# R7FA8M1AH register map
Vendor: Renesas; Series: RA8; File version: 1.2
CPU: CM85 r0p0, little endian, MPU, FPU, VTOR, 4 interrupt priority bits
Registers are 32-bit, read-write, reset 0x0 unless marked. A register's access mark holds for its fields unless they carry their own. Offsets are from the block's base; [hi:lo] are bit positions; 'fields as' and 'values as' point back to an identical list.

## SCI0 (part 1 of 2) — Serial Communication Interface 0
Base 0x40358000
Same registers: SCI1 0x40358100, SCI2 0x40358200, SCI3 0x40358300, SCI4 0x40358400, SCI9 0x40358900, SCI0_NS 0x50358000, SCI1_NS 0x50358100, SCI2_NS 0x50358200, SCI3_NS 0x50358300, SCI4_NS 0x50358400, SCI9_NS 0x50358900
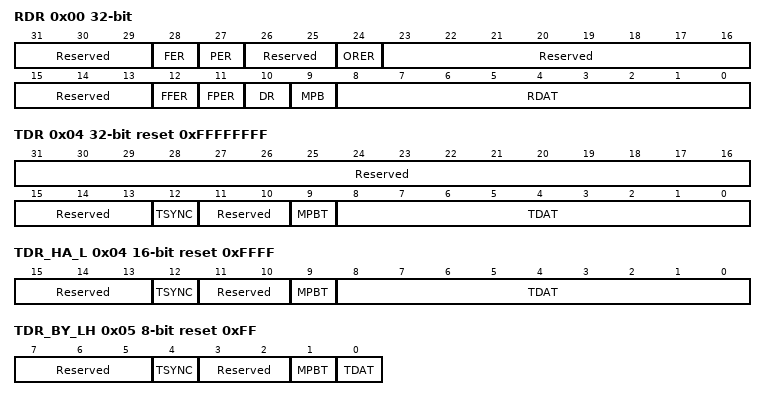
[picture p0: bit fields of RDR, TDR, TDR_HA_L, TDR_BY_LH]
0x00 RDR ro — Received Data Register
  [31:29] Reserved — These bits are read as 000.
  [28] FER — Framing Error Flag
    0=No framing error occurred; 1=A framing error has occurred
  [27] PER — Parity Error Flag
    0=No parity error occurred; 1=A parity error has occurred
  [26:25] Reserved — These bits are read as 00.
  [24] ORER — Overrun error flag
    0=No overrun error occurred; 1=An overrun error has occurred
  [23:13] Reserved — These bits are read as 00000000000.
  [12] FFER — Framing error flag
    0=No framing error occurred at the first data of received-FIFO (RDR); 1=A framing error has occurred at the first data of received-FIFO (RDR)
  [11] FPER — Parity error flag
    0=No parity error occurred at the first data of received-FIFO (RDR); 1=A parity error has occurred at the first data of received-FIFO (RDR)
  [10] DR — Receive data ready flag
    0=Receiving is in progress, or no received data has remained in received-FIFO (RDR) after normally completed receiving; 1=Next receive data has not been received for a period after normal completed receiving
  [9] MPB — Multiprocessor bit flag
    0=Data transmission cycles; 1=ID transmission cycles
  [8:0] RDAT — Received data.
0x04 TDR reset 0xFFFFFFFF — Transmission Data Register
  [31:16] Reserved — These bits are read as 1111111111111111. The write value should be 1111111111111111.
  [15:13] Reserved — These bits are read as 111. The write value should be 111.
  [12] TSYNC — Transmit sync data bit.
    0=Start bit outputs data Sync; 1=Start bit outputs command Sync
  [11:10] Reserved — These bits are read as 11. The write value should be 11.
  [9] MPBT — Multi-processor transfer bit flag
    0=Data transmission cycles; 1=ID transmission cycles
  [8:0] TDAT — Transmission data.
0x04 TDR_HA_L 16-bit reset 0xFFFF — Transmission Data Register
  [15:13] Reserved — These bits are read as 111. The write value should be 111.
  [12] TSYNC — Transmit sync data bit.
    values as TDR.TSYNC
  [11:10] Reserved — These bits are read as 11. The write value should be 11.
  [9] MPBT — Multi-processor transfer bit flag
    0=Data transmission cycles; 1=ID transmission cycles
  [8:0] TDAT — Transmission data.
0x04 TDR_BY_LL 8-bit reset 0xFF — Transmission Data Register
  [7:0] TDAT — Transmission data.
0x05 TDR_BY_LH 8-bit reset 0xFF — Transmission Data Register
  [7:5] Reserved — These bits are read as 111. The write value should be 111.
  [4] TSYNC — Transmit sync data bit.
    values as TDR.TSYNC
  [3:2] Reserved — These bits are read as 11. The write value should be 11.
  [1] MPBT — Multi-processor transfer bit flag
    0=Data transmission cycles; 1=ID transmission cycles
  [0] TDAT — Transmission data.
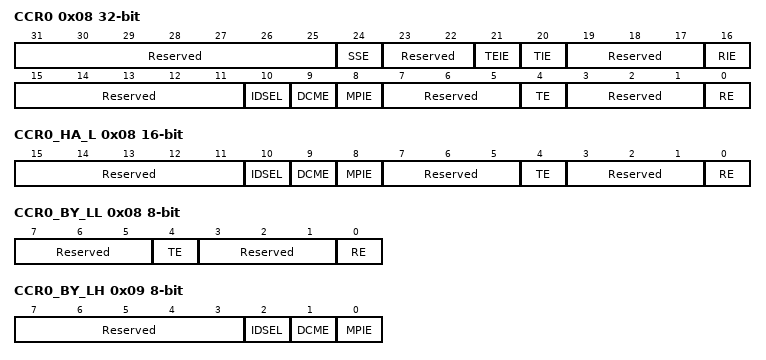
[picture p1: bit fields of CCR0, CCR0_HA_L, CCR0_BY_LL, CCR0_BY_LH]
0x08 CCR0 — Common Control Register 0
  [31:25] Reserved — These bits are read as 0000000. The write value should be 0000000.
  [24] SSE — SSn# Pin Function Enable
    0=SSn# pin function is disabled; 1=SSn# pin function is enabled
  [23:22] Reserved — These bits are read as 00. The write value should be 00.
  [21] TEIE — Transmit End Interrupt Enable
    0=A TEI interrupt request is disabled; 1=A TEI interrupt request is enabled
  [20] TIE — Transmit Interrupt Enable
    0=A TXI interrupt request is disabled; 1=A TXI interrupt request is enabled
  [19:17] Reserved — These bits are read as 000. The write value should be 000.
  [16] RIE — Receive Interrupt Enable
    0=RXI and ERI interrupt requests are disabled; 1=RXI and ERI interrupt requests are enabled
  [15:11] Reserved — These bits are read as 00000. The write value should be 00000.
  [10] IDSEL — ID frame select Bit
    0=It's always compared data in spite of the value of the MPB bit; 1=It's compared data when the MPB bit is “1” ( ID frame ) only
  [9] DCME read-modifies — Data Compare Match Enable
    0=Address match function is disabled; 1=Address match function is enabled
  [8] MPIE read-modifies — Multi-Processor Interrupt Enable
    0=Normal reception; 1=When the data with the multi-processor bit set to "0" is received, the data is not read, and setting the status flags RDRF,ORER FER ,MER ,SYER , PFER and SBER to "1" is disabled. When the data with the multiprocessor bit set to "1" is received, the MPIE bit is automatically cleared to "0", and normal reception is resumed.
  [7:5] Reserved — These bits are read as 000. The write value should be 000.
  [4] TE — Transmit Enable
    0=Serial transmission is disabled; 1=Serial transmission is enabled
  [3:1] Reserved — These bits are read as 000. The write value should be 000.
  [0] RE — Receive Enable
    0=Serial reception is disabled; 1=Serial reception is enabled
0x08 CCR0_HA_L 16-bit — Common Control Register 0
  [15:11] Reserved — These bits are read as 00000. The write value should be 00000.
  [10] IDSEL — ID frame select Bit
    values as CCR0.IDSEL
  [9] DCME read-modifies — Data Compare Match Enable
    values as CCR0.DCME
  [8] MPIE read-modifies — Multi-Processor Interrupt Enable
    values as CCR0.MPIE
  [7:5] Reserved — These bits are read as 000. The write value should be 000.
  [4] TE — Transmit Enable
    values as CCR0.TE
  [3:1] Reserved — These bits are read as 000. The write value should be 000.
  [0] RE — Receive Enable
    values as CCR0.RE
0x08 CCR0_BY_LL 8-bit — Common Control Register 0
  [7:5] Reserved — These bits are read as 000. The write value should be 000.
  [4] TE — Transmit Enable
    values as CCR0.TE
  [3:1] Reserved — These bits are read as 000. The write value should be 000.
  [0] RE — Receive Enable
    values as CCR0.RE
0x09 CCR0_BY_LH 8-bit — Common Control Register 0
  [7:3] Reserved — These bits are read as 00000. The write value should be 00000.
  [2] IDSEL — ID frame select Bit
    values as CCR0.IDSEL
  [1] DCME read-modifies — Data Compare Match Enable
    values as CCR0.DCME
  [0] MPIE read-modifies — Multi-Processor Interrupt Enable
    values as CCR0.MPIE
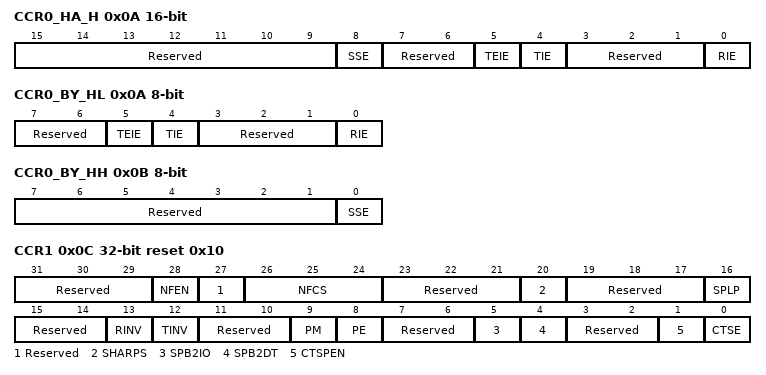
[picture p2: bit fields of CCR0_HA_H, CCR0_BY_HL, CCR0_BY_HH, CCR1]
0x0A CCR0_HA_H 16-bit — Common Control Register 0
  [15:9] Reserved — These bits are read as 0000000. The write value should be 0000000.
  [8] SSE — SSn# Pin Function Enable
    values as CCR0.SSE
  [7:6] Reserved — These bits are read as 00. The write value should be 00.
  [5] TEIE — Transmit End Interrupt Enable
    values as CCR0.TEIE
  [4] TIE — Transmit Interrupt Enable
    values as CCR0.TIE
  [3:1] Reserved — These bits are read as 000. The write value should be 000.
  [0] RIE — Receive Interrupt Enable
    values as CCR0.RIE
0x0A CCR0_BY_HL 8-bit — Common Control Register 0
  [7:6] Reserved — These bits are read as 00. The write value should be 00.
  [5] TEIE — Transmit End Interrupt Enable
    values as CCR0.TEIE
  [4] TIE — Transmit Interrupt Enable
    values as CCR0.TIE
  [3:1] Reserved — These bits are read as 000. The write value should be 000.
  [0] RIE — Receive Interrupt Enable
    values as CCR0.RIE
0x0B CCR0_BY_HH 8-bit — Common Control Register 0
  [7:1] Reserved — These bits are read as 0000000. The write value should be 0000000.
  [0] SSE — SSn# Pin Function Enable
    values as CCR0.SSE
0x0C CCR1 reset 0x10 — Common Control Register 1
  [31:29] Reserved — These bits are read as 000. The write value should be 000.
  [28] NFEN — Digital Noise Filter Function Enable
    0=Noise cancellation function for the RXDn/TXDn input signal is disabled; 1=Noise cancellation function for the RXDn/TXDn input signal is enabled
  [27] Reserved — This bit is read as 0. The write value should be 0.
  [26:24] NFCS — Noise Filter Clock Select
    0=The base clock divided by 1 is used with the noise filter; 1=The on-chip baud rate generator clock divided by 1 is used; 0b=with the noise filter; 2=The on-chip baud rate generator clock divided by 2 is used; 0b=with the noise filter; 3=The on-chip baud rate generator clock divided by 4 is used; 0b=with the noise filter; 4=The on-chip baud rate generator clock divided by 8 is used; 0b=with the noise filter; other=others (Settings other than above are prohibited.)
  [23:21] Reserved — These bits are read as 000. The write value should be 000.
  [20] SHARPS — TxD/RxD Pin Multiplexing Select
    0=The TxD and RxD pins are independent; 1=The TxD and RxD signals are multiplexed on the same pin
  [19:17] Reserved — These bits are read as 000. The write value should be 000.
  [16] SPLP — Serial communication Port LoopBack
    0=Normal mode; 1=Loopback mode
  [15:14] Reserved — These bits are read as 00. The write value should be 00.
  [13] RINV — RxD invert bit
    0=Received data from RxD is input directly; 1=Received data from RxD is inverted and input
  [12] TINV — TxD invert bit
    0=Transmit data is output directly to TxD; 1=Transmit data is inverted and output to TxD
  [11:10] Reserved — These bits are read as 00. The write value should be 00.
  [9] PM — Parity Mode
    0=Selects even parity; 1=Selects odd parity
  [8] PE — Parity Enable
    0=Parity bit addition or checking is not performed; 1=The parity bit is added or checked
  [7:6] Reserved — These bits are read as 00. The write value should be 00.
  [5] SPB2IO — Serial port break I/O bit
    0=The value of SPB2DT bit isn't output in TxD terminal; 1=The value of SPB2DT bit is output in TxD terminal
  [4] SPB2DT — Serial port break data select bit
    0=Low level is output in TxD terminal, when TINV is 0; 1=High level is output in TxD terminal, when TINV is 1
  [3:2] Reserved — These bits are read as 00. The write value should be 00.
  [1] CTSPEN — CTS external terminal enable bit.
    0=Alternate setting for using either CTS / RTS function as one terminal; 1=Dedicated setting to simultaneously use CTS / RTS function with 2 pins; 0b=at the same time
  [0] CTSE — CTS Enable
    0=CTS function is disabled (RTS output function is enabled); 1=CTS function is enabled
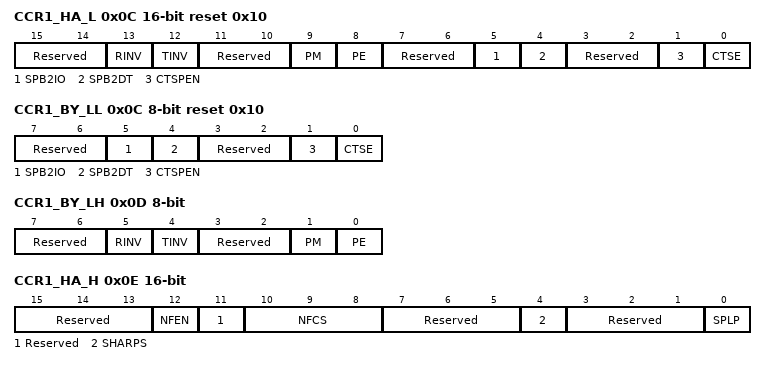
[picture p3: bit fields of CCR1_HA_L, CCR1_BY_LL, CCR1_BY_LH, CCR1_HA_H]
0x0C CCR1_HA_L 16-bit reset 0x10 — Common Control Register 1
  [15:14] Reserved — These bits are read as 00. The write value should be 00.
  [13] RINV — RxD invert bit
    values as CCR1.RINV
  [12] TINV — TxD invert bit
    values as CCR1.TINV
  [11:10] Reserved — These bits are read as 00. The write value should be 00.
  [9] PM — Parity Mode
    0=Selects even parity; 1=Selects odd parity
  [8] PE — Parity Enable
    values as CCR1.PE
  [7:6] Reserved — These bits are read as 00. The write value should be 00.
  [5] SPB2IO — Serial port break I/O bit
    values as CCR1.SPB2IO
  [4] SPB2DT — Serial port break data select bit
    values as CCR1.SPB2DT
  [3:2] Reserved — These bits are read as 00. The write value should be 00.
  [1] CTSPEN — CTS external terminal enable bit.
    values as CCR1.CTSPEN
  [0] CTSE — CTS Enable
    values as CCR1.CTSE
0x0C CCR1_BY_LL 8-bit reset 0x10 — Common Control Register 1
  [7:6] Reserved — These bits are read as 00. The write value should be 00.
  [5] SPB2IO — Serial port break I/O bit
    values as CCR1.SPB2IO
  [4] SPB2DT — Serial port break data select bit
    values as CCR1.SPB2DT
  [3:2] Reserved — These bits are read as 00. The write value should be 00.
  [1] CTSPEN — CTS external terminal enable bit.
    values as CCR1.CTSPEN
  [0] CTSE — CTS Enable
    values as CCR1.CTSE
0x0D CCR1_BY_LH 8-bit — Common Control Register 1
  [7:6] Reserved — These bits are read as 00. The write value should be 00.
  [5] RINV — RxD invert bit
    values as CCR1.RINV
  [4] TINV — TxD invert bit
    values as CCR1.TINV
  [3:2] Reserved — These bits are read as 00. The write value should be 00.
  [1] PM — Parity Mode
    0=Selects even parity; 1=Selects odd parity
  [0] PE — Parity Enable
    values as CCR1.PE
0x0E CCR1_HA_H 16-bit — Common Control Register 1
  [15:13] Reserved — These bits are read as 000. The write value should be 000.
  [12] NFEN — Digital Noise Filter Function Enable
    values as CCR1.NFEN
  [11] Reserved — This bit is read as 0. The write value should be 0.
  [10:8] NFCS — Noise Filter Clock Select
    values as CCR1.NFCS
  [7:5] Reserved — These bits are read as 000. The write value should be 000.
  [4] SHARPS — TxD/RxD Pin Multiplexing Select
    values as CCR1.SHARPS
  [3:1] Reserved — These bits are read as 000. The write value should be 000.
  [0] SPLP — Serial communication Port LoopBack
    0=Normal mode; 1=Loopback mode
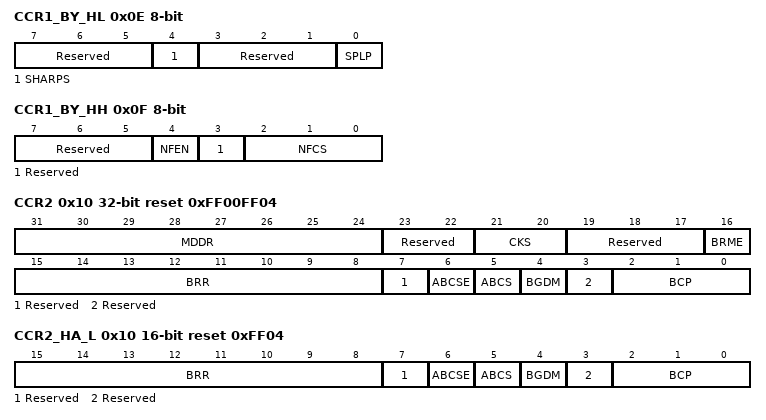
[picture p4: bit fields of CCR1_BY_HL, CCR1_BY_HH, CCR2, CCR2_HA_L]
0x0E CCR1_BY_HL 8-bit — Common Control Register 1
  [7:5] Reserved — These bits are read as 000. The write value should be 000.
  [4] SHARPS — TxD/RxD Pin Multiplexing Select
    values as CCR1.SHARPS
  [3:1] Reserved — These bits are read as 000. The write value should be 000.
  [0] SPLP — Serial communication Port LoopBack
    0=Normal mode; 1=Loopback mode
0x0F CCR1_BY_HH 8-bit — Common Control Register 1
  [7:5] Reserved — These bits are read as 000. The write value should be 000.
  [4] NFEN — Digital Noise Filter Function Enable
    values as CCR1.NFEN
  [3] Reserved — This bit is read as 0. The write value should be 0.
  [2:0] NFCS — Noise Filter Clock Select
    values as CCR1.NFCS
0x10 CCR2 reset 0xFF00FF04 — Common Control Register 2
  [31:24] MDDR — MDDR corrects the bit rate adjusted by the BRR setting
  [23:22] Reserved — These bits are read as 00. The write value should be 00.
  [21:20] CKS — Clock Select
    0=TCLK clock; 1=TCLK/4 clock; 2=TCLK/16 clock; 3=TCLK/64 clock
  [19:17] Reserved — These bits are read as 000. The write value should be 000.
  [16] BRME — Bit Modulation Enable
    0=Bit rate modulation function is disabled; 1=Bit rate modulation function is enabled
  [15:8] BRR — BRR is an 8-bit register that adjusts the bit rate.
  [7] Reserved — This bit is read as 0. The write value should be 0.
  [6] ABCSE — Asynchronous Mode Base Clock Select1
    0b=and ABCS; 0b=frequency is output from the baud rate generator
  [5] ABCS — Asynchronous Mode Base Clock Select
    0=Selects 16 base clock cycles for 1-bit period; 1=Selects 8 base clock cycles for 1-bit period
  [4] BGDM — Baud Rate Generator Double-Speed Mode Select
    0=Baud rate generator outputs the clock with normal frequency; 1=Baud rate generator outputs the clock with doubled frequency
  [3] Reserved — This bit is read as 0. The write value should be 0.
  [2:0] BCP — Basic clock pulse
0x10 CCR2_HA_L 16-bit reset 0xFF04 — Common Control Register 2
  [15:8] BRR — BRR is an 8-bit register that adjusts the bit rate.
  [7] Reserved — This bit is read as 0. The write value should be 0.
  [6] ABCSE — Asynchronous Mode Base Clock Select1
    values as CCR2.ABCSE
  [5] ABCS — Asynchronous Mode Base Clock Select
    values as CCR2.ABCS
  [4] BGDM — Baud Rate Generator Double-Speed Mode Select
    values as CCR2.BGDM
  [3] Reserved — This bit is read as 0. The write value should be 0.
  [2:0] BCP — Basic clock pulse
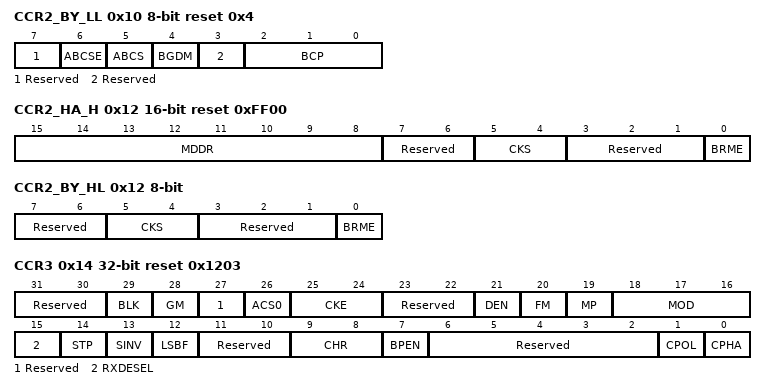
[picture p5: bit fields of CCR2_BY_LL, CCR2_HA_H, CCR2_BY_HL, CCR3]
0x10 CCR2_BY_LL 8-bit reset 0x4 — Common Control Register 2
  [7] Reserved — This bit is read as 0. The write value should be 0.
  [6] ABCSE — Asynchronous Mode Base Clock Select1
    values as CCR2.ABCSE
  [5] ABCS — Asynchronous Mode Base Clock Select
    values as CCR2.ABCS
  [4] BGDM — Baud Rate Generator Double-Speed Mode Select
    values as CCR2.BGDM
  [3] Reserved — This bit is read as 0. The write value should be 0.
  [2:0] BCP — Basic clock pulse
0x11 CCR2_BY_LH 8-bit reset 0xFF — Common Control Register 2
  [7:0] BRR — BRR is an 8-bit register that adjusts the bit rate.
0x12 CCR2_HA_H 16-bit reset 0xFF00 — Common Control Register 2
  [15:8] MDDR — MDDR corrects the bit rate adjusted by the BRR setting
  [7:6] Reserved — These bits are read as 00. The write value should be 00.
  [5:4] CKS — Clock Select
    values as CCR2.CKS
  [3:1] Reserved — These bits are read as 000. The write value should be 000.
  [0] BRME — Bit Modulation Enable
    values as CCR2.BRME
0x12 CCR2_BY_HL 8-bit — Common Control Register 2
  [7:6] Reserved — These bits are read as 00. The write value should be 00.
  [5:4] CKS — Clock Select
    values as CCR2.CKS
  [3:1] Reserved — These bits are read as 000. The write value should be 000.
  [0] BRME — Bit Modulation Enable
    values as CCR2.BRME
0x13 CCR2_BY_HH 8-bit reset 0xFF — Common Control Register 2
  [7:0] MDDR — MDDR corrects the bit rate adjusted by the BRR setting
0x14 CCR3 reset 0x1203 — Common Control Register 3
  [31:30] Reserved — These bits are read as 00. The write value should be 00.
  [29] BLK — Block transfer mode
    0=Operates in non-block transfer mode; 1=Operates in block transfer mode
  [28] GM — GSM Mode
    0=Operates in non-GSM mode; 1=It operates in GSM mode
  [27] Reserved — This bit is read as 0. The write value should be 0.
  [26] ACS0 — Asynchronous Mode Clock Source Select
    0=External clock input; 1=Logical AND of two clock cycles output from the TMR
  [25:24] CKE — Clock Enable
    0=On-chip baud rate generator; 0b=The SCKn pin is available for use as an I/O port in accord with the I/O; 0b=port settings; 1=On-chip baud rate generator; 0b=The clock with the same frequency as the bit rate is output from the; 0b=SCKn pin; 0b=• The clock with a frequency 16 times the bit rate should be input from; 0b=the SCKn pin. (when CCR2.ABCS bit is “0”) Input a clock signal with; 0b=a frequency 8 times the bit rate when the CCR2.ABCS bit is “1”; 0b=• The TMR clock can be used. The SCKn pin is available for use as an; 0b=I/O port in accord with the I/O port settings when the TMR clock is used; 0=On-chip baud rate generator The SCKn pin functions as I/O port; 0=Output disabled (The SCKn pin is available for use as an I/O port; 0b=in accord with the I/O port settings.); 1=Clock output; 0=Output fixed low; 2=Output fixed high
  [23:22] Reserved — These bits are read as 00. The write value should be 00.
  [21] DEN — Driver control Enable
    0=RS-485 driver control function is enable; 0=RS-485 driver control function is disable
  [20] FM — FIFO Mode Select
    0=Non-FIFO mode; 1=FIFO mode
  [19] MP — Multi-Processor mode
    0=Multi-processor communications function is disabled; 1=Multi-processor communications function is enabled
  [18:16] MOD — communication MODe select bit
    0=Asynchronous; 1=Smart card interface; 2=Clock snchronous; 3=Simple-SPI; 4=Simple-I2C; 5=Manchester; 6=Simple-LIN; 7=Prohibit
  [15] RXDESEL — Asynchronous Start Bit Edge Detection Select
    values as ACS0
  [14] STP — Stop Bit Length
    0=1 stop bit; 1=2 stop bits
  [13] SINV — Transmitted/Received Data Invert
    0=TDR contents are transmitted to TSR as they are; 0b=RSR contents are stored to RDR as they are; 1=TDR contents are inverted before being transmitted to TSR; 0b=RSR contents are inverted and stored to RDR
  [12] LSBF — LSB first select bit
    0=MSB first; 1=LSB first
  [11:10] Reserved — These bits are read as 00. The write value should be 00.
  [9:8] CHR — CHaRacter length select
    0=Transmit/receive in 9-bit length; 1=Transmit/receive in 9-bit length; 2=Transmit/receive in 8-bit length; 3=Transmit/receive in 7-bit length
  [7] BPEN — Synchronizer ByPass Enable
    0=Synchronizer-bypass desable; 1=Synchronizer-bypass enable
  [6:2] Reserved — These bits are read as 00000. The write value should be 00000.
  [1] CPOL — Clock Polarity Setting
    0=Set RSPCK low during idle; 1=Set RSPCK high during idle
  [0] CPHA — Clock Phase Setting
    0=Select data sampling on leading edge, data change on trailing edge; 1=Select data change on leading edge, data sampling on trailing edge
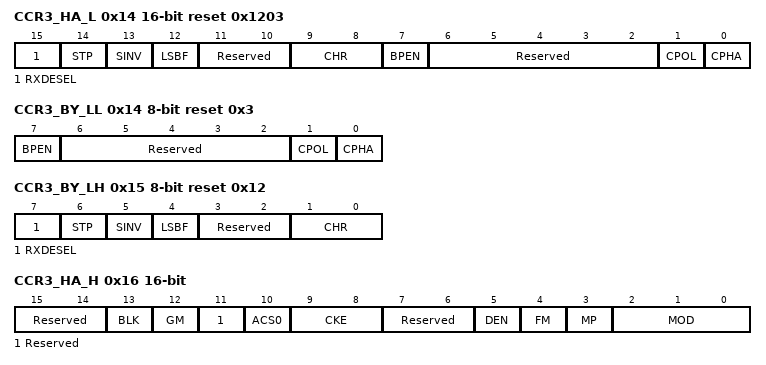
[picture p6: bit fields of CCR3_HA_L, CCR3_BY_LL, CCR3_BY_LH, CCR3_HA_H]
0x14 CCR3_HA_L 16-bit reset 0x1203 — Common Control Register 3
  [15] RXDESEL — Asynchronous Start Bit Edge Detection Select
    values as CCR3.ACS0
  [14] STP — Stop Bit Length
    0=1 stop bit; 1=2 stop bits
  [13] SINV — Transmitted/Received Data Invert
    values as CCR3.SINV
  [12] LSBF — LSB first select bit
    0=MSB first; 1=LSB first
  [11:10] Reserved — These bits are read as 00. The write value should be 00.
  [9:8] CHR — CHaRacter length select
    values as CCR3.CHR
  [7] BPEN — Synchronizer ByPass Enable
    0=Synchronizer-bypass desable; 1=Synchronizer-bypass enable
  [6:2] Reserved — These bits are read as 00000. The write value should be 00000.
  [1] CPOL — Clock Polarity Setting
    0=Set RSPCK low during idle; 1=Set RSPCK high during idle
  [0] CPHA — Clock Phase Setting
    values as CCR3.CPHA
0x14 CCR3_BY_LL 8-bit reset 0x3 — Common Control Register 3
  [7] BPEN — Synchronizer ByPass Enable
    0=Synchronizer-bypass desable; 1=Synchronizer-bypass enable
  [6:2] Reserved — These bits are read as 00000. The write value should be 00000.
  [1] CPOL — Clock Polarity Setting
    0=Set RSPCK low during idle; 1=Set RSPCK high during idle
  [0] CPHA — Clock Phase Setting
    values as CCR3.CPHA
0x15 CCR3_BY_LH 8-bit reset 0x12 — Common Control Register 3
  [7] RXDESEL — Asynchronous Start Bit Edge Detection Select
    values as CCR3.ACS0
  [6] STP — Stop Bit Length
    0=1 stop bit; 1=2 stop bits
  [5] SINV — Transmitted/Received Data Invert
    values as CCR3.SINV
  [4] LSBF — LSB first select bit
    0=MSB first; 1=LSB first
  [3:2] Reserved — These bits are read as 00. The write value should be 00.
  [1:0] CHR — CHaRacter length select
    values as CCR3.CHR
0x16 CCR3_HA_H 16-bit — Common Control Register 3
  [15:14] Reserved — These bits are read as 00. The write value should be 00.
  [13] BLK — Block transfer mode
    values as CCR3.BLK
  [12] GM — GSM Mode
    0=Operates in non-GSM mode; 1=It operates in GSM mode
  [11] Reserved — This bit is read as 0. The write value should be 0.
  [10] ACS0 — Asynchronous Mode Clock Source Select
    values as CCR3.ACS0
  [9:8] CKE — Clock Enable
    values as CCR3.CKE
  [7:6] Reserved — These bits are read as 00. The write value should be 00.
  [5] DEN — Driver control Enable
    values as CCR3.DEN
  [4] FM — FIFO Mode Select
    0=Non-FIFO mode; 1=FIFO mode
  [3] MP — Multi-Processor mode
    values as CCR3.MP
  [2:0] MOD — communication MODe select bit
    values as CCR3.MOD
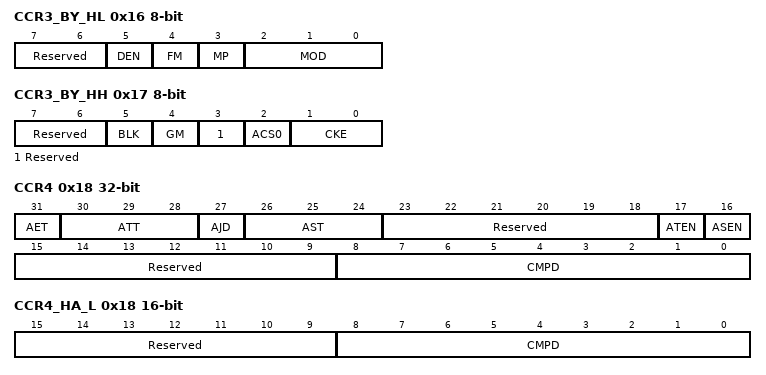
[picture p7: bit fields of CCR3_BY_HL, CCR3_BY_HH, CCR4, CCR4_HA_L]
0x16 CCR3_BY_HL 8-bit — Common Control Register 3
  [7:6] Reserved — These bits are read as 00. The write value should be 00.
  [5] DEN — Driver control Enable
    values as CCR3.DEN
  [4] FM — FIFO Mode Select
    0=Non-FIFO mode; 1=FIFO mode
  [3] MP — Multi-Processor mode
    values as CCR3.MP
  [2:0] MOD — communication MODe select bit
    values as CCR3.MOD
0x17 CCR3_BY_HH 8-bit — Common Control Register 3
  [7:6] Reserved — These bits are read as 00. The write value should be 00.
  [5] BLK — Block transfer mode
    values as CCR3.BLK
  [4] GM — GSM Mode
    0=Operates in non-GSM mode; 1=It operates in GSM mode
  [3] Reserved — This bit is read as 0. The write value should be 0.
  [2] ACS0 — Asynchronous Mode Clock Source Select
    values as CCR3.ACS0
  [1:0] CKE — Clock Enable
    values as CCR3.CKE
0x18 CCR4 — Common Control Register 4
  [31] AET — Adjustment Duty control level select
    0=Expand the low period by adjustment of the rising edge of TxD; 0b=waveform(when CCR1.TINV is 0); 1=Expand the high period by adjustment of the falling edge of TxD; 0b=waveform(when CCR1.TINV is 0.)
  [30:28] ATT — Adjustmen Transmission timing value
    0=No adjustment; other=others (internal base clock * the value of ATT[2:0])
  [27] AJD — Adjustment Direction for sampling timing
    0=The sampling timing is adjusted after the default timing; 1=The sampling timing is adjusted before the default timing
  [26:24] AST — Adjustment Sampling Timing value
    0=No adjustment (The sampling at default timing); other=others (internal base clock * the setting value of AST[2:0].)
  [23:18] Reserved — These bits are read as 000000. The write value should be 000000.
  [17] ATEN — Adjustment enable bit for transmit waveform
    0=Adjustment transmit waveform function is disabled; 1=Adjustment transmit waveform function is enabled
  [16] ASEN — Adjustment enable bit for sampling timing
    0=Adjustment sampling timing function is disabled; 1=Adjustment sampling timing function is enabled
  [15:9] Reserved — These bits are read as 0000000. The write value should be 0000000.
  [8:0] CMPD — Compare Match Data
0x18 CCR4_HA_L 16-bit — Common Control Register 4
  [15:9] Reserved — These bits are read as 0000000. The write value should be 0000000.
  [8:0] CMPD — Compare Match Data
0x18 CCR4_BY_LL 8-bit — Common Control Register 4
  [7:0] CMPD — Compare Match Data
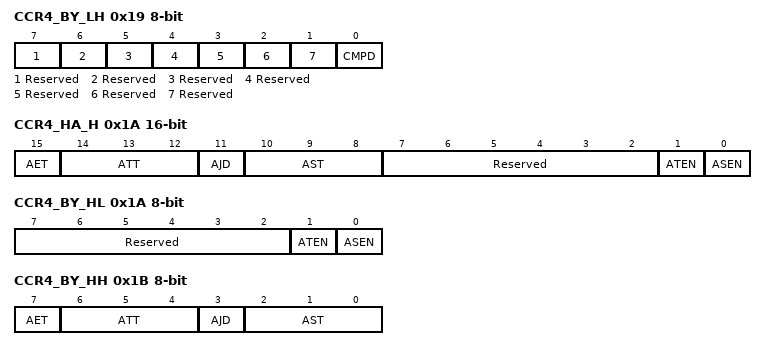
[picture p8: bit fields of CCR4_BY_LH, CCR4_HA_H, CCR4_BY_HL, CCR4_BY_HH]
0x19 CCR4_BY_LH 8-bit — Common Control Register 4
  [7] Reserved — This bit is read as 0. The write value should be 0.
  [6] Reserved — This bit is read as 0. The write value should be 0.
  [5] Reserved — This bit is read as 0. The write value should be 0.
  [4] Reserved — This bit is read as 0. The write value should be 0.
  [3] Reserved — This bit is read as 0. The write value should be 0.
  [2] Reserved — This bit is read as 0. The write value should be 0.
  [1] Reserved — This bit is read as 0. The write value should be 0.
  [0] CMPD — Compare Match Data
0x1A CCR4_HA_H 16-bit — Common Control Register 4
  [15] AET — Adjustment Duty control level select
    values as CCR4.AET
  [14:12] ATT — Adjustmen Transmission timing value
    values as CCR4.ATT
  [11] AJD — Adjustment Direction for sampling timing
    values as CCR4.AJD
  [10:8] AST — Adjustment Sampling Timing value
    values as CCR4.AST
  [7:2] Reserved — These bits are read as 000000. The write value should be 000000.
  [1] ATEN — Adjustment enable bit for transmit waveform
    values as CCR4.ATEN
  [0] ASEN — Adjustment enable bit for sampling timing
    values as CCR4.ASEN
0x1A CCR4_BY_HL 8-bit — Common Control Register 4
  [7:2] Reserved — These bits are read as 000000. The write value should be 000000.
  [1] ATEN — Adjustment enable bit for transmit waveform
    values as CCR4.ATEN
  [0] ASEN — Adjustment enable bit for sampling timing
    values as CCR4.ASEN
0x1B CCR4_BY_HH 8-bit — Common Control Register 4
  [7] AET — Adjustment Duty control level select
    values as CCR4.AET
  [6:4] ATT — Adjustmen Transmission timing value
    values as CCR4.ATT
  [3] AJD — Adjustment Direction for sampling timing
    values as CCR4.AJD
  [2:0] AST — Adjustment Sampling Timing value
    values as CCR4.AST
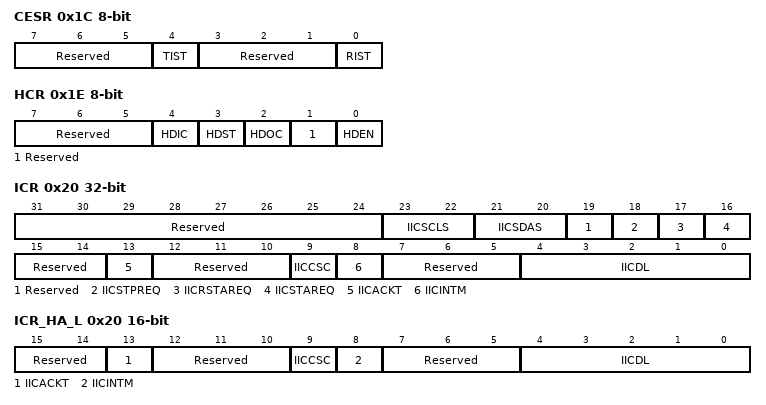
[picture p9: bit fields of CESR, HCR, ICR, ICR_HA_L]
0x1C CESR 8-bit ro — Communication Enable Status Register
  [7:5] Reserved — These bits are read as 000.
  [4] TIST — Internal status of TE signal
    0=Internal status of TE is "0"; 1=Internal status of TE is "1"
  [3:1] Reserved — These bits are read as 000.
  [0] RIST — Internal status of RE signal
    0=Internal status of RE is "0"; 1=Internal status of RE is "1"
0x1E HCR 8-bit — HBS valid mode Control Register
  [7:5] Reserved — These bits are read as 000. The write value should be 000.
  [4] HDIC — HDC valid mode start bit Initialize Control
    0=Output terminal is initialized for each start bit; 1=Output terminal is not initialized for each start bit
  [3] HDST — HDC valid mode STart bit
    0=Start bit is started from TXD terminal; 1=Start bit is started from TXDB terminal
  [2] HDOC — HDC valid mode Output Control
    0=Select 1 terminal output mode; 1=Select 2 terminal output mode
  [1] Reserved — This bit is read as 0. The write value should be 0.
  [0] HDEN — HDC valid mode Enable
    0=Disabled Half Data valid mode; 1=Enabled Half Data valid mode
0x20 ICR — Simple-I2C Control Register
  [31:24] Reserved — These bits are read as 00000000. The write value should be 00000000.
  [23:22] IICSCLS — SCL Output Select
    0=Serial clock output; 1=Generate a start, restart, or stop condition; 2=Output the low level on the SSCLn pin; 3=Place the SSCLn pin in the high-impedance state
  [21:20] IICSDAS — SDA Output Select
    0=Serial data output; 1=Generate a start, restart, or stop condition; 2=Output the low level on the SSDAn pin; 3=Place the SSDAn pin in the high-impedance state
  [19] Reserved — This bit is read as 0. The write value should be 0.
  [18] IICSTPREQ — Stop Condition Generation
    0=A stop condition is not generated; 1=A stop condition is generated
  [17] IICRSTAREQ — Restart Condition Generation
    0=A restart condition is not generated; 1=A restart condition is generated
  [16] IICSTAREQ — Start Condition Generation
    0=A start condition is not generated; 1=A start condition is generated
  [15:14] Reserved — These bits are read as 00. The write value should be 00.
  [13] IICACKT — ACK Transmission Data
    0=ACK transmission; 1=NACK transmission and reception of ACK/NACK
  [12:10] Reserved — These bits are read as 000. The write value should be 000.
  [9] IICCSC — Clock Synchronization
    0=No synchronization with the clock signal; 1=Synchronization with the clock signal
  [8] IICINTM — I2C Interrupt Mode Select
    0=Use ACK/NACK interrupts; 1=Use reception and transmission interrupts
  [7:5] Reserved — These bits are read as 000. The write value should be 000.
  [4:0] IICDL — SSDA Delay Output Select
    0=No output delay; other=others (（IICDL-1 ) to IIDCDL cycles.); 0b=The delay is in the clock cycles from the on-chip baud rate generator
0x20 ICR_HA_L 16-bit — Simple-I2C Control Register
  [15:14] Reserved — These bits are read as 00. The write value should be 00.
  [13] IICACKT — ACK Transmission Data
    values as ICR.IICACKT
  [12:10] Reserved — These bits are read as 000. The write value should be 000.
  [9] IICCSC — Clock Synchronization
    values as ICR.IICCSC
  [8] IICINTM — I2C Interrupt Mode Select
    values as ICR.IICINTM
  [7:5] Reserved — These bits are read as 000. The write value should be 000.
  [4:0] IICDL — SSDA Delay Output Select
    values as ICR.IICDL
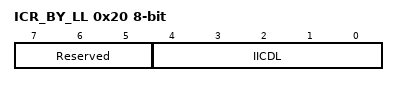
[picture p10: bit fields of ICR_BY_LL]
0x20 ICR_BY_LL 8-bit — Simple-I2C Control Register
  [7:5] Reserved — These bits are read as 000. The write value should be 000.
  [4:0] IICDL — SSDA Delay Output Select
    values as ICR.IICDL
